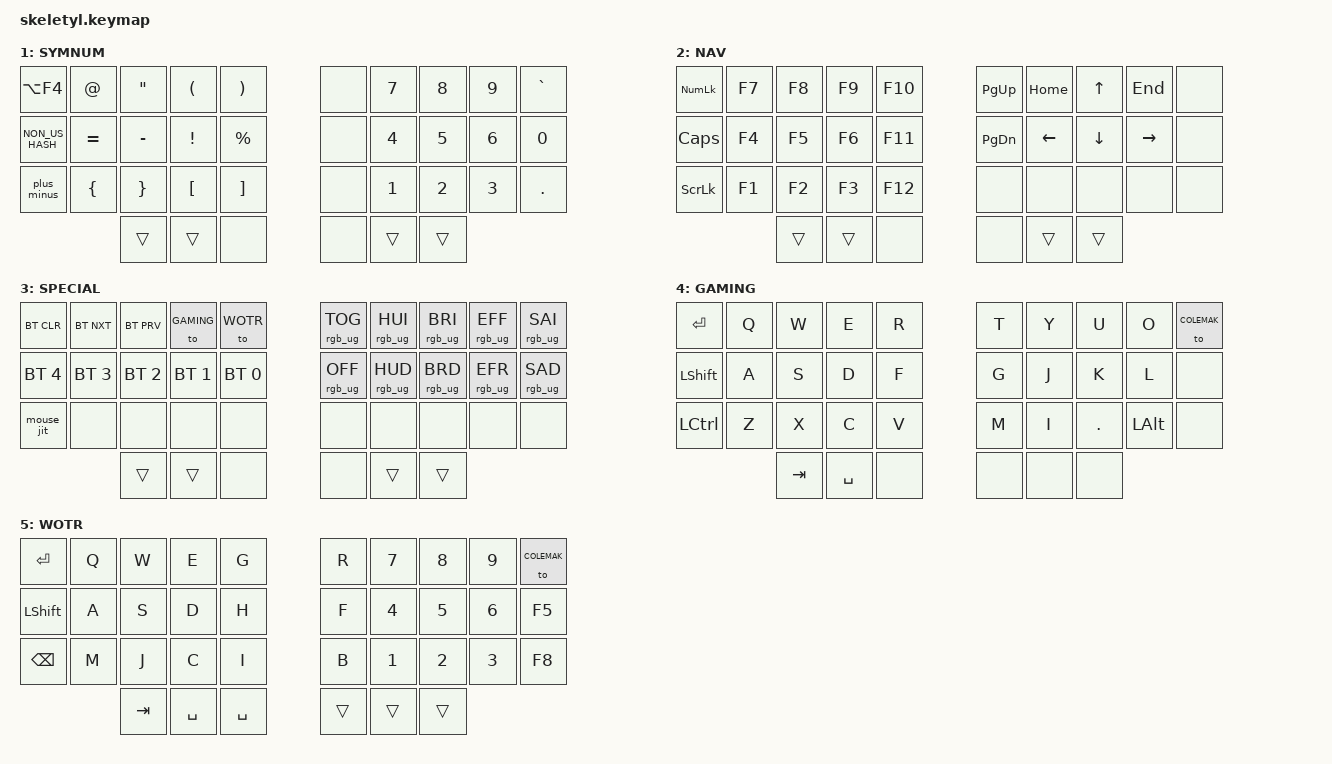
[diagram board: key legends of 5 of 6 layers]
/*
 * Copyright (c) 2020 The ZMK Contributors
 *
 * SPDX-License-Identifier: MIT
 */
#include <behaviors.dtsi>
#include <dt-bindings/zmk/bt.h>
#include <dt-bindings/zmk/keys.h>
#include <dt-bindings/zmk/rgb.h>

// Layer Definitions
#define COLEMAK 0
#define SYMNUM 1
#define NAV 2
#define SPECIAL 3
#define GAMING 4
#define WOTR 5

/ {
    // --- Combos ---
    combos {
        compatible = "zmk,combos";
        combo_esc { timeout-ms = <40>; key-positions = <1 2>; bindings = <&kp ESC>; };
        combo_underscore { timeout-ms = <35>; key-positions = <12 13>; bindings = <&kp UNDER>; };
        combo_quote { timeout-ms = <35>; key-positions = <17 18>; bindings = <&kp SQT>; };
        combo_del { timeout-ms = <40>; key-positions = <10 11>; bindings = <&kp DEL>; };
        combo_bslsh { timeout-ms = <40>; key-positions = <7 8>; bindings = <&kp NON_US_BSLH>; };
        combo_caps { timeout-ms = <40>; key-positions = <12 17>; bindings = <&caps_word>; };
    };

    // --- Conditional Layers (Tri Layer) ---
    conditional_layers {
        compatible = "zmk,conditional-layers";
        tri_layer { if-layers = <SYMNUM NAV>; then-layer = <SPECIAL>; }; // Activate SPECIAL if SYMNUM & NAV are active
    };

    // --- Custom Behaviors ---
    behaviors {
        // Homerow Mods Hold-Tap Definition
        hm: homerow_mods {
            compatible = "zmk,behavior-hold-tap";
            label = "HOMEROW_MODS";
            #binding-cells = <2>;
            tapping-term-ms = <220>;
            quick-tap-ms = <125>; // Optional: ms before quick tap ends
            flavor = "tap-preferred"; // Tapping is preferred over holding
            bindings = <&kp>, <&kp>; // Behavior expects two bindings: <hold>, <tap>
        };
        // Add other custom behaviors here if needed
    };

    // --- Macros ---
    macros {
        plus_minus: plus_minus {
            compatible = "zmk,behavior-macro";
            label = "PLUS_MINUS";
            #binding-cells = <0>;
            bindings =
                <¯o_press &kp LALT>, // Press Left Alt
                <¯o_tap &kp KP_N2 &kp KP_N4 &kp KP_N1>, // Tap Numpad 2, 4, 1 while Alt is held
                <¯o_release &kp LALT>; // Release Left Alt
        };

        mouse_jit: mouse_jit {
            compatible = "zmk,behavior-macro";
            label = "MOUSE_JIT";
            #binding-cells = <0>;
            bindings = <¯o_press &kp A>, <¯o_pause_for_release>, <¯o_wait_ms 10000>, <¯o_release &kp A>; // Press A, wait, Release A
        };
    };

    &led_strip {
        chain-length = <18>;
    };

    // --- Keymap ---
    keymap {
        compatible = "zmk,keymap";

        // Layer 0: Colemak Base Layer
        colemak_layer {
            label = "COLEMAK";
            bindings = <
                // Left Hand                                                    // Right Hand
                &kp Q          &kp W          &kp F             &kp P        &kp G           &kp J          &kp L          &kp U          &kp Y       &kp SEMI
                &hm LGUI A     &hm LALT R     &hm LSHFT S       &hm LCTRL T  &kp D           &kp H          &hm RCTRL N    &hm RSHFT E    &hm LALT I  &hm RGUI O
                &kp Z          &kp X          &kp C             &kp V        &kp B           &kp K          &kp M          &kp COMMA      &kp DOT     &kp FSLH
                                             &mt LSHIFT ENTER  < SYMNUM SPACE     &none          &none          &kp BACKSPACE  < NAV TAB
            >;
            // Sensor bindings for encoders on this layer
            // Format: <&behavior_LEFT_CW &behavior_LEFT_CCW   &behavior_RIGHT_CW &behavior_RIGHT_CCW>
            // Using &inc_dec_kp requires CONFIG_ZMK_SENSOR_KEYCODE_ENABLE=y (usually default)
            // Alternative: <&kp RIGHT &kp LEFT &kp RIGHT &kp LEFT>
            sensor-bindings = <&inc_dec_kp C_VOL_UP C_VOL_DN   &inc_dec_kp RIGHT LEFT>; // Example: Left=Volume, Right=Arrows
        };

        // Layer 1: Symbols & Numbers
        symnum_layer {
            label = "SYMNUM";
            bindings = <
                // Left Hand                                                    // Right Hand
                &kp LA(F4)     &kp AT         &kp DQT           &kp LPAR     &kp RPAR        &none          &kp N7         &kp N8         &kp N9      &kp GRAVE
                &kp NON_US_HASH &kp EQUAL     &kp MINUS         &kp EXCL     &kp PRCNT       &none          &kp N4         &kp N5         &kp N6      &kp N0
                &plus_minus    &kp LBRC       &kp RBRC          &kp LBKT     &kp RBKT        &none          &kp N1         &kp N2         &kp N3      &kp DOT
                                              &trans            &trans           &none          &none          &trans         &trans
            >;
            sensor-bindings = <&inc_dec_kp C_VOL_UP C_VOL_DN   &inc_dec_kp RIGHT LEFT>; // Keep same bindings or change per layer
        };

        // Layer 2: Navigation & Function Keys
        nav_layer {
            label = "NAV";
            bindings = <
                // Left Hand                                                    // Right Hand
                &kp KP_NUMLOCK &kp F7         &kp F8            &kp F9       &kp F10         &kp PG_UP      &kp HOME       &kp UP         &kp END     &none
                &kp CAPS       &kp F4         &kp F5            &kp F6       &kp F11         &kp PG_DN      &kp LEFT       &kp DOWN       &kp RIGHT   &none
                &kp SCROLLLOCK &kp F1         &kp F2            &kp F3       &kp F12         &none          &none          &none          &none       &none
                                              &trans            &trans           &none          &none          &trans         &trans
            >;
            sensor-bindings = <&inc_dec_kp PG_UP PG_DN &inc_dec_kp PG_UP PG_DN>; // Example: Both Page Up/Down
        };

        // Layer 3: Special Keys (Activated by SYMNUM + NAV)
        special_layer {
            label = "SPECIAL";
            bindings = <
                // Left Hand                                                    // Right Hand
                &bt BT_CLR     &bt BT_NXT     &bt BT_PRV        &to GAMING      &to WOTR         &rgb_ug RGB_TOG  &rgb_ug RGB_HUI  &rgb_ug RGB_BRI  &rgb_ug RGB_EFF  &rgb_ug RGB_SAI
                &bt BT_SEL 4   &bt BT_SEL 3   &bt BT_SEL 2      &bt BT_SEL 1  &bt BT_SEL 0     &rgb_ug RGB_OFF  &rgb_ug RGB_HUD  &rgb_ug RGB_BRD  &rgb_ug RGB_EFR  &rgb_ug RGB_SAD
                &mouse_jit     &none          &none             &none         &none            &none            &none            &none            &none            &none
                                              &trans            &trans           &none            &none            &trans           &trans
            >;
             // Example RGB control on encoders
            sensor-bindings = <&rgb_ug HUI HUD   &rgb_ug BRI BRD>;
        };

        // Layer 4: Gaming Layer
        gaming_layer {
            label = "GAMING";
            bindings = <
                // Left Hand                                                    // Right Hand
                &kp ENTER      &kp Q          &kp W             &kp E        &kp R           &kp T          &kp Y          &kp U          &kp O       &to COLEMAK
                &kp LSHFT      &kp A          &kp S             &kp D        &kp F           &kp G          &kp J          &kp K          &kp L       &none
                &kp LCTRL      &kp Z          &kp X             &kp C        &kp V           &kp M          &kp I          &kp DOT        &kp LALT    &none
                                              &kp TAB           &kp SPACE        &none          &none          &none          &none
            >;
            sensor-bindings = <&inc_dec_kp PG_DN PG_UP &inc_dec_kp PG_DN PG_UP>;
        };

        // Layer 5: WotR Layer
        WotR { // Note: Layer name should not contain spaces if referenced by index/macro
            label = "WOTR";
            bindings = <
                // Left Hand                                                    // Right Hand
                &kp ENTER      &kp Q          &kp W             &kp E        &kp G           &kp R          &kp N7         &kp N8         &kp N9      &to COLEMAK
                &kp LSHFT      &kp A          &kp S             &kp D        &kp H           &kp F          &kp N4         &kp N5         &kp N6      &kp F5
                &kp BSPC       &kp M          &kp J             &kp C        &kp I           &kp B          &kp N1         &kp N2         &kp N3      &kp F8
                                              &kp TAB           &kp SPACE        &kp SPACE      &trans         &trans         &trans
            >;
            sensor-bindings = <&inc_dec_kp PG_UP PG_DN>;
        };
    }; // End keymap
}; // End root node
